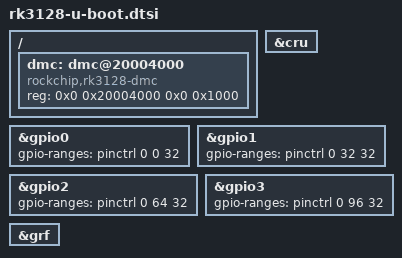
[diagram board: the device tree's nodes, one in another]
// SPDX-License-Identifier: GPL-2.0+

#include "rockchip-u-boot.dtsi"

/ {
	dmc: dmc@20004000 {
		compatible = "rockchip,rk3128-dmc", "syscon";
		reg = <0x0 0x20004000 0x0 0x1000>;
		bootph-all;
	};
};

&cru {
	bootph-all;
};

&gpio0 {
	gpio-ranges = <&pinctrl 0 0 32>;
};

&gpio1 {
	gpio-ranges = <&pinctrl 0 32 32>;
};

&gpio2 {
	gpio-ranges = <&pinctrl 0 64 32>;
};

&gpio3 {
	gpio-ranges = <&pinctrl 0 96 32>;
};

&grf {
	bootph-all;
};
